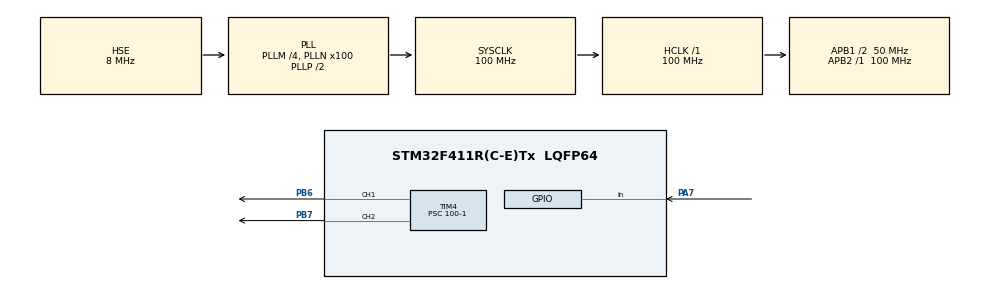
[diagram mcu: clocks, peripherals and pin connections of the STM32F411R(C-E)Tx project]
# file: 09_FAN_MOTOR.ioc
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Mcu.Family=STM32F4
Mcu.Name=STM32F411R(C-E)Tx
Mcu.Package=LQFP64
NVIC.PriorityGroup=NVIC_PRIORITYGROUP_4
PA13.Mode=Serial_Wire
PA13.Signal=SYS_JTMS-SWDIO
PA14.Mode=Serial_Wire
PA14.Signal=SYS_JTCK-SWCLK
PA7.Signal=GPIO_Input
PB6.Signal=S_TIM4_CH1
PB7.Signal=S_TIM4_CH2
PH0\ -\ OSC_IN.Mode=HSE-External-Oscillator
PH0\ -\ OSC_IN.Signal=RCC_OSC_IN
PH1\ -\ OSC_OUT.Mode=HSE-External-Oscillator
PH1\ -\ OSC_OUT.Signal=RCC_OSC_OUT
ProjectManager.HeapSize=0x200
ProjectManager.StackSize=0x400
ProjectManager.TargetToolchain=STM32CubeIDE
RCC.48MHZClocksFreq_Value=50000000
RCC.AHBFreq_Value=100000000
RCC.APB1CLKDivider=RCC_HCLK_DIV2
RCC.APB1Freq_Value=50000000
RCC.APB1TimFreq_Value=100000000
RCC.APB2Freq_Value=100000000
RCC.APB2TimFreq_Value=100000000
RCC.CortexFreq_Value=100000000
RCC.HCLKFreq_Value=100000000
RCC.HSE_VALUE=8000000
RCC.HSI_VALUE=16000000
RCC.LSE_VALUE=32768
RCC.PLLM=4
RCC.PLLN=100
RCC.PLLSourceVirtual=RCC_PLLSOURCE_HSE
RCC.SYSCLKFreq_VALUE=100000000
RCC.SYSCLKSource=RCC_SYSCLKSOURCE_PLLCLK
RCC.VCOOutputFreq_Value=200000000
SH.S_TIM4_CH1.0=TIM4_CH1,PWM Generation1 CH1
SH.S_TIM4_CH2.0=TIM4_CH2,PWM Generation2 CH2
TIM4.Channel-PWM\ Generation1\ CH1=TIM_CHANNEL_1
TIM4.Channel-PWM\ Generation2\ CH2=TIM_CHANNEL_2
TIM4.Period=1000-1
TIM4.Prescaler=100-1
VP_TIM4_VS_ClockSourceINT.Mode=Internal
board=custom

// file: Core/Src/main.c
/* USER CODE BEGIN Header */
/**
  ******************************************************************************
  * @file           : main.c
  * @brief          : Main program body
  ******************************************************************************
  * @attention
  *
  * Copyright (c) 2025 STMicroelectronics.
  * All rights reserved.
  *
  * This software is licensed under terms that can be found in the LICENSE file
  * in the root directory of this software component.
  * If no LICENSE file comes with this software, it is provided AS-IS.
  *
  ******************************************************************************
  */
/* USER CODE END Header */
#include "main.h"
#include "tim.h"
#include "gpio.h"

/* USER CODE BEGIN Includes */
#include "button.h"
/* USER CODE END Includes */

/* USER CODE BEGIN PV */
uint8_t fanMode = 0;
/* USER CODE END PV */

void SystemClock_Config(void);

int main(void)
{

  /* MCU Configuration--------------------------------------------------------*/

  /* Reset of all peripherals, Initializes the Flash interface and the Systick. */
  HAL_Init();

  /* Configure the system clock */
  SystemClock_Config();

  /* Initialize all configured peripherals */
  MX_GPIO_Init();
  MX_TIM4_Init();
  /* USER CODE BEGIN 2 */
  HAL_TIM_PWM_Start(&htim4, TIM_CHANNEL_1);
  HAL_TIM_PWM_Start(&htim4, TIM_CHANNEL_2);
  /* USER CODE END 2 */

  /* Infinite loop */
  /* USER CODE BEGIN WHILE */
  while (1)
  {
	  if (buttonGetPressed(0)) {
		  fanMode++;
		  if (fanMode == 4) {
			  fanMode = 0;
		  }
	  }

	  switch (fanMode) {
		case 0:
		case 2:
			TIM4->CCR1 = 0;
			TIM4->CCR2 = 0;
			break;
		case 1:
			TIM4->CCR1 = 700;
			TIM4->CCR2 = 0;
			break;
		case 3:
			TIM4->CCR1 = 0;
			TIM4->CCR2 = 700;
			break;

		default:
			TIM4->CCR1 = 0;
			TIM4->CCR2 = 0;
			break;
	}
    /* USER CODE END WHILE */

  }
}

void SystemClock_Config(void)
{
  RCC_OscInitTypeDef RCC_OscInitStruct = {0};
  RCC_ClkInitTypeDef RCC_ClkInitStruct = {0};

  /** Configure the main internal regulator output voltage
  */
  __HAL_RCC_PWR_CLK_ENABLE();
  __HAL_PWR_VOLTAGESCALING_CONFIG(PWR_REGULATOR_VOLTAGE_SCALE1);

  /** Initializes the RCC Oscillators according to the specified parameters
  * in the RCC_OscInitTypeDef structure.
  */
  RCC_OscInitStruct.OscillatorType = RCC_OSCILLATORTYPE_HSE;
  RCC_OscInitStruct.HSEState = RCC_HSE_ON;
  RCC_OscInitStruct.PLL.PLLState = RCC_PLL_ON;
  RCC_OscInitStruct.PLL.PLLSource = RCC_PLLSOURCE_HSE;
  RCC_OscInitStruct.PLL.PLLM = 4;
  RCC_OscInitStruct.PLL.PLLN = 100;
  RCC_OscInitStruct.PLL.PLLP = RCC_PLLP_DIV2;
  RCC_OscInitStruct.PLL.PLLQ = 4;
  if (HAL_RCC_OscConfig(&RCC_OscInitStruct) != HAL_OK)
  {
    Error_Handler();
  }

  /** Initializes the CPU, AHB and APB buses clocks
  */
  RCC_ClkInitStruct.ClockType = RCC_CLOCKTYPE_HCLK|RCC_CLOCKTYPE_SYSCLK
                              |RCC_CLOCKTYPE_PCLK1|RCC_CLOCKTYPE_PCLK2;
  RCC_ClkInitStruct.SYSCLKSource = RCC_SYSCLKSOURCE_PLLCLK;
  RCC_ClkInitStruct.AHBCLKDivider = RCC_SYSCLK_DIV1;
  RCC_ClkInitStruct.APB1CLKDivider = RCC_HCLK_DIV2;
  RCC_ClkInitStruct.APB2CLKDivider = RCC_HCLK_DIV1;

  if (HAL_RCC_ClockConfig(&RCC_ClkInitStruct, FLASH_LATENCY_3) != HAL_OK)
  {
    Error_Handler();
  }
}

void Error_Handler(void)
{
  __disable_irq();
  while (1)
  {
  }
}
